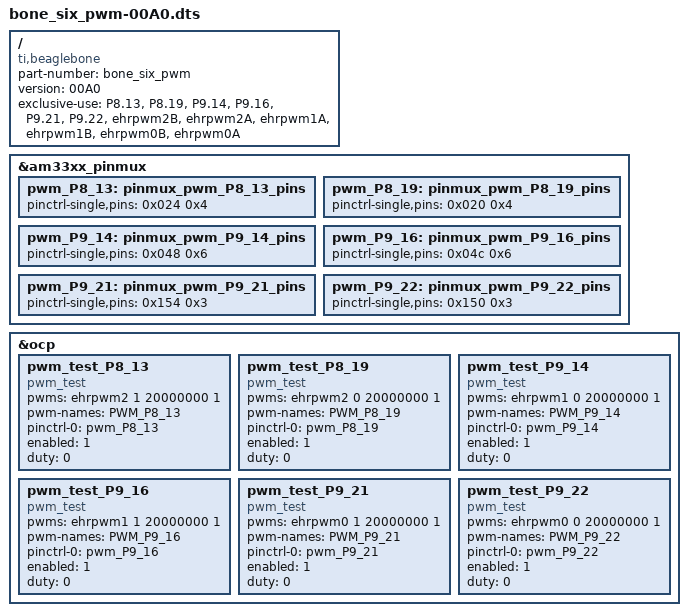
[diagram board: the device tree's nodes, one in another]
/*
 * Copyright (C) 2013 CircuitCo
 * Copyright (C) 2013 Texas Instruments
 *
 * This program is free software; you can redistribute it and/or modify
 * it under the terms of the GNU General Public License version 2 as
 * published by the Free Software Foundation.
 *
 * Modified by Nicholas Wernicke
 */
/dts-v1/;
/plugin/;

/ {
        compatible = "ti,beaglebone", "ti,beaglebone-black";

        /* identification */
        part-number = "bone_six_pwm";
        version = "00A0";

        /* state the resources this cape uses */
        exclusive-use =
                /* the pin header uses */
                "P8.13",                /* pwm: ehrpwm2B */
                "P8.19",                /* pwm: ehrpwm2A */
                "P9.14",                /* pwm: ehrpwm1A */
                "P9.16",                /* pwm: ehrpwm1B */
                "P9.21",                /* pwm: ehrpwm0B */
                "P9.22",                /* pwm: ehrpwm0A */
                /* the hardware IP uses */
                "ehrpwm2B",
                "ehrpwm2A",
                "ehrpwm1A",
                "ehrpwm1B",
                "ehrpwm0B",
                "ehrpwm0A";

        fragment@0 {
                target = <&am33xx_pinmux>;
                __overlay__ {
                        pwm_P8_13: pinmux_pwm_P8_13_pins {
                                pinctrl-single,pins = <0x024  0x4>; /*
P8_13 (ZCZ ball T10) | MODE 4 */
                        };
                        pwm_P8_19: pinmux_pwm_P8_19_pins {
                                pinctrl-single,pins = <0x020  0x4>; /*
P8_19 (ZCZ ball U10) | MODE 4 */
                        };
                        pwm_P9_14: pinmux_pwm_P9_14_pins {
                                pinctrl-single,pins = <0x048  0x6>; /*
P9_14 (ZCZ ball U14) | MODE 6 */
                        };
                        pwm_P9_16: pinmux_pwm_P9_16_pins {
                                pinctrl-single,pins = <0x04c  0x6>; /*
P9_16 (ZCZ ball T14) | MODE 6 */
                        };
                        pwm_P9_21: pinmux_pwm_P9_21_pins {
                                pinctrl-single,pins = <0x154  0x3>; /*
P9_21 (ZCZ ball B17) | MODE 3 */
                        };
                        pwm_P9_22: pinmux_pwm_P9_22_pins {
                                pinctrl-single,pins = <0x150  0x3>; /*
P9_22 (ZCZ ball A17) | MODE 3 */
                        };
                };
        };

        fragment@1 {
                target = <&ocp>;
                __overlay__ {
                        pwm_test_P8_13 {
                                compatible      = "pwm_test";
                                pwms            = <&ehrpwm2 1 20000000
1>;
                                pwm-names       = "PWM_P8_13";
                                pinctrl-names   = "default";
                                pinctrl-0       = <&pwm_P8_13>;
                                enabled         = <1>;
                                duty            = <0>;
                                status          = "okay";
                        };

                        pwm_test_P8_19 {
                                compatible      = "pwm_test";
                                pwms            = <&ehrpwm2 0 20000000
1>;
                                pwm-names       = "PWM_P8_19";
                                pinctrl-names   = "default";
                                pinctrl-0       = <&pwm_P8_19>;
                                enabled         = <1>;
                                duty            = <0>;
                                status          = "okay";
                        };

                        pwm_test_P9_14 {
                                compatible      = "pwm_test";
                                pwms            = <&ehrpwm1 0 20000000
1>;
                                pwm-names       = "PWM_P9_14";
                                pinctrl-names       = "default";
                                pinctrl-0   = <&pwm_P9_14>;
                                enabled         = <1>;
                                duty            = <0>;
                                status          = "okay";
                        };

                        pwm_test_P9_16 {
                                compatible      = "pwm_test";
                                pwms            = <&ehrpwm1 1 20000000
1>;
                                pwm-names       = "PWM_P9_16";
                                pinctrl-names       = "default";
                                pinctrl-0   = <&pwm_P9_16>;
                                enabled         = <1>;
                                duty            = <0>;
                                status          = "okay";
                        };

                        pwm_test_P9_21 {
                                compatible      = "pwm_test";
                                pwms            = <&ehrpwm0 1 20000000
1>;
                                pwm-names       = "PWM_P9_21";
                                pinctrl-names       = "default";
                                pinctrl-0   = <&pwm_P9_21>;
                                enabled         = <1>;
                                duty            = <0>;
                                status          = "okay";
                        };

                        pwm_test_P9_22 {
                                compatible      = "pwm_test";
                                pwms            = <&ehrpwm0 0 20000000
1>;
                                pwm-names       = "PWM_P9_22";
                                pinctrl-names       = "default";
                                pinctrl-0   = <&pwm_P9_22>;
                                enabled         = <1>;
                                duty            = <0>;
                                status          = "okay";
                        };
                };
        };
};

/*
 * dtc -O dtb -o bone_six_pwm-00A0.dtbo -b 0 -@ bone_six_pwm-00A0.dts
 * export SLOTS=/sys/devices/bone_capemgr.8/slots
 * echo am33xx_pwm > $SLOTS
 * echo bone_six_pwm > $SLOTS
*/

